# Maia SDR register map
Vendor: Daniel Estevez; Series: Maia SDR; File version: 0.6.0
Maia SDR IP core
Registers are 32-bit, read-only, no defined reset value unless marked. A register's access mark holds for its fields unless they carry their own. Offsets are from the block's base; lines under a group give offsets from that group; [hi:lo] are bit positions; {n}, {i} and the like mark numbered series; 'fields as' and 'values as' point back to an identical list; <NAME> marks a mode.

## Memory map
0x00000000 Maia_SDR size 0x40 — Maia SDR IP core

## Maia_SDR — Maia SDR IP core
Base 0x00000000
0x00 product_id
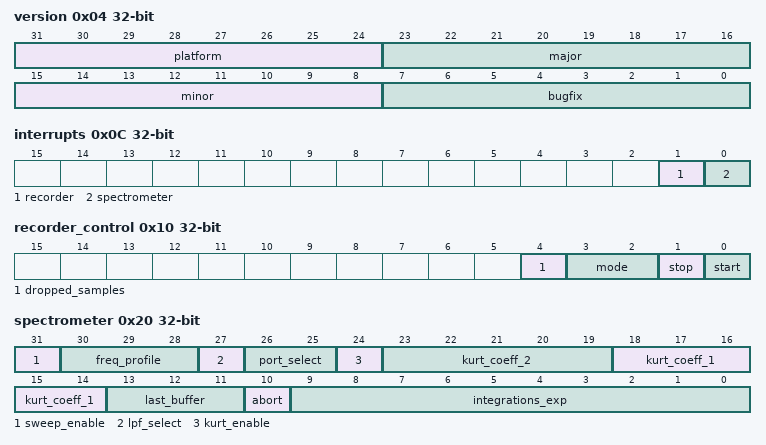
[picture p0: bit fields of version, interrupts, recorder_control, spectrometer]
0x04 version
  [31:24] platform, [23:16] major, [15:8] minor, [7:0] bugfix
0x08 control rw
  [0] sdr_reset
0x0C interrupts
  [1] recorder, [0] spectrometer
0x10 recorder_control rw
  [4] dropped_samples ro, [3:2] mode, [1] stop wo, [0] start wo
0x14 recorder_next_address
  [31:0] next_address
0x20 spectrometer rw
  [31] sweep_enable, [30:28] freq_profile, [27] lpf_select, [26:25] port_select, [24] kurt_enable, [23:19] kurt_coeff_2, [18:14] kurt_coeff_1, [13:11] last_buffer ro, [10] abort wo, [9:0] integrations_exp
0x24 spectrometer2
  [6:0] sweep_cnt — Current sweep step (0..31)

## Licence text in the file
SPDX-License-Identifier: MIT Copyright (C) Daniel Estevez 2022-2024
